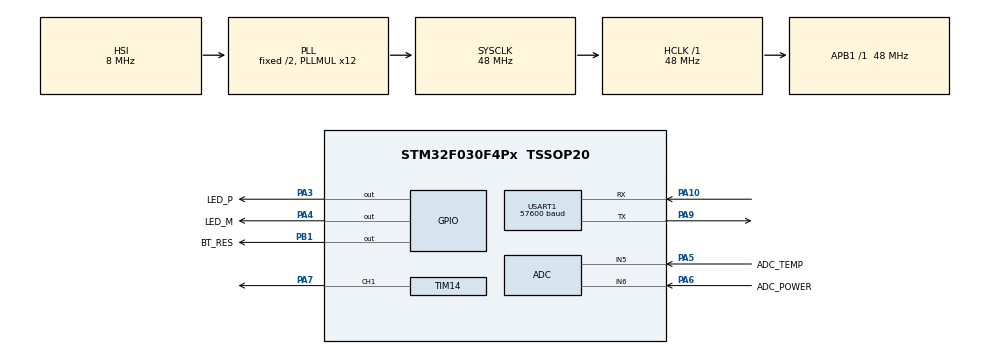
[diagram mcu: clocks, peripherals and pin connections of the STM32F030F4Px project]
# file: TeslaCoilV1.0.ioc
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ADC.ContinuousConvMode=ENABLE
ADC.DMAContinuousRequests=ENABLE
ADC.EOCSelection=ADC_EOC_SINGLE_CONV
ADC.SamplingTime=ADC_SAMPLETIME_239CYCLES_5
Dma.ADC.1.Direction=DMA_PERIPH_TO_MEMORY
Dma.ADC.1.Instance=DMA1_Channel1
Dma.ADC.1.MemDataAlignment=DMA_MDATAALIGN_WORD
Dma.ADC.1.MemInc=DMA_MINC_ENABLE
Dma.ADC.1.Mode=DMA_CIRCULAR
Dma.ADC.1.PeriphDataAlignment=DMA_PDATAALIGN_WORD
Dma.ADC.1.PeriphInc=DMA_PINC_DISABLE
Dma.ADC.1.Priority=DMA_PRIORITY_LOW
Dma.Request0=USART1_TX
Dma.Request1=ADC
Dma.USART1_TX.0.Direction=DMA_MEMORY_TO_PERIPH
Dma.USART1_TX.0.Instance=DMA1_Channel2
Dma.USART1_TX.0.MemDataAlignment=DMA_MDATAALIGN_BYTE
Dma.USART1_TX.0.MemInc=DMA_MINC_ENABLE
Dma.USART1_TX.0.Mode=DMA_NORMAL
Dma.USART1_TX.0.PeriphDataAlignment=DMA_PDATAALIGN_BYTE
Dma.USART1_TX.0.PeriphInc=DMA_PINC_DISABLE
Dma.USART1_TX.0.Priority=DMA_PRIORITY_MEDIUM
Mcu.Family=STM32F0
Mcu.Name=STM32F030F4Px
Mcu.Package=TSSOP20
NVIC.DMA1_Channel1_IRQn=true\:3\:0\:true\:false\:true\:false\:true
NVIC.DMA1_Channel2_3_IRQn=true\:1\:0\:true\:false\:true\:false\:true
NVIC.TIM1_BRK_UP_TRG_COM_IRQn=true\:2\:0\:true\:true\:true\:2\:true\:true
NVIC.USART1_IRQn=true\:1\:0\:true\:true\:true\:1\:true\:true
PA10.GPIO_PuPd=GPIO_NOPULL
PA10.Mode=Asynchronous
PA10.Signal=USART1_RX
PA13.Mode=Serial_Wire
PA13.Signal=SYS_SWDIO
PA14.Mode=Serial_Wire
PA14.Signal=SYS_SWCLK
PA3.GPIO_Label=LED_P
PA3.Signal=GPIO_Output
PA4.GPIO_Label=LED_M
PA4.PinState=GPIO_PIN_SET
PA4.Signal=GPIO_Output
PA5.GPIO_Label=ADC_TEMP
PA5.Mode=IN5
PA5.Signal=ADC_IN5
PA6.GPIO_Label=ADC_POWER
PA6.Mode=IN6
PA6.Signal=ADC_IN6
PA7.Signal=S_TIM14_CH1
PA9.GPIO_PuPd=GPIO_PULLUP
PA9.Mode=Asynchronous
PA9.Signal=USART1_TX
PB1.GPIO_Label=BT_RES
PB1.GPIO_ModeDefaultOutputPP=GPIO_MODE_OUTPUT_OD
PB1.GPIO_PuPd=GPIO_PULLUP
PB1.PinState=GPIO_PIN_SET
PB1.Signal=GPIO_Output
ProjectManager.HeapSize=0x200
ProjectManager.StackSize=0x400
ProjectManager.TargetToolchain=EWARM V8
RCC.AHBFreq_Value=48000000
RCC.APB1Freq_Value=48000000
RCC.APB1TimFreq_Value=48000000
RCC.HCLKFreq_Value=48000000
RCC.PLLMUL=RCC_PLL_MUL12
RCC.SYSCLKFreq_VALUE=48000000
RCC.SYSCLKSource=RCC_SYSCLKSOURCE_PLLCLK
SH.S_TIM14_CH1.0=TIM14_CH1,PWM Generation1 CH1
TIM1.Prescaler=47
TIM14.Channel=TIM_CHANNEL_1
TIM14.OCFastMode_PWM=TIM_OCFAST_ENABLE
TIM14.Period=499
TIM14.Prescaler=47
TIM14.Pulse=1
TIM16.AutoReloadPreload=TIM_AUTORELOAD_PRELOAD_ENABLE
TIM16.Period=999
TIM16.Prescaler=47
USART1.BaudRate=57600
USART1.VirtualMode-Asynchronous=VM_ASYNC
VP_ADC_TempSens_Input.Mode=IN-TempSens
VP_ADC_Vref_Input.Mode=IN-Vrefint
VP_TIM14_VS_ClockSourceINT.Mode=Enable_Timer
VP_TIM16_VS_ClockSourceINT.Mode=Enable_Timer
VP_TIM1_VS_ClockSourceINT.Mode=Internal
board=custom

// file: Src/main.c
/* USER CODE BEGIN Header */
/**
  ******************************************************************************
  * @file           : main.c
  * @brief          : Main program body
  ******************************************************************************
  * @attention
  *
  * <h2><center>&copy; Copyright (c) 2020 STMicroelectronics.
  * All rights reserved.</center></h2>
  *
  * This software component is licensed by ST under BSD 3-Clause license,
  * the "License"; You may not use this file except in compliance with the
  * License. You may obtain a copy of the License at:
  *                        opensource.org/licenses/BSD-3-Clause
  *
  ******************************************************************************
  */
/* USER CODE END Header */

#include "main.h"
#include "adc.h"
#include "dma.h"
#include "tim.h"
#include "usart.h"
#include "gpio.h"

/* USER CODE BEGIN Includes */

#include "System.h"
#include "LED.h"
#include "Connection.h"
#include "ProcessInterrupterData.h"

/* USER CODE END Includes */

void SystemClock_Config(void);
static void MX_NVIC_Init(void);

int main(void)
{

  /* MCU Configuration--------------------------------------------------------*/

  /* Reset of all peripherals, Initializes the Flash interface and the Systick. */
  HAL_Init();

  /* Configure the system clock */
  SystemClock_Config();

  /* Initialize all configured peripherals */
  MX_GPIO_Init();
  MX_DMA_Init();
  MX_TIM14_Init();
  MX_USART1_UART_Init();
  MX_TIM16_Init();
  MX_ADC_Init();
  MX_TIM1_Init();

  /* Initialize interrupts */
  MX_NVIC_Init();

  /* Infinite loop */
  while (1)
  {

    /* USER CODE BEGIN 3 */

    if(htim16.Instance->SR & TIM_SR_UIF) {
      htim16.Instance->SR &= ~TIM_SR_UIF;

      processLed();
      processBluetoothEventTimer();
      processConnectionEventTimer();
      processModulaterInterrupter();
    }

    processSystem();

  }
  /* USER CODE END 3 */
}

void SystemClock_Config(void)
{
  RCC_OscInitTypeDef RCC_OscInitStruct = {0};
  RCC_ClkInitTypeDef RCC_ClkInitStruct = {0};
  RCC_PeriphCLKInitTypeDef PeriphClkInit = {0};

  /** Initializes the CPU, AHB and APB busses clocks
  */
  RCC_OscInitStruct.OscillatorType = RCC_OSCILLATORTYPE_HSI|RCC_OSCILLATORTYPE_HSI14;
  RCC_OscInitStruct.HSIState = RCC_HSI_ON;
  RCC_OscInitStruct.HSI14State = RCC_HSI14_ON;
  RCC_OscInitStruct.HSICalibrationValue = RCC_HSICALIBRATION_DEFAULT;
  RCC_OscInitStruct.HSI14CalibrationValue = 16;
  RCC_OscInitStruct.PLL.PLLState = RCC_PLL_ON;
  RCC_OscInitStruct.PLL.PLLSource = RCC_PLLSOURCE_HSI;
  RCC_OscInitStruct.PLL.PLLMUL = RCC_PLL_MUL12;
  RCC_OscInitStruct.PLL.PREDIV = RCC_PREDIV_DIV1;
  if (HAL_RCC_OscConfig(&RCC_OscInitStruct) != HAL_OK)
  {
    Error_Handler();
  }
  /** Initializes the CPU, AHB and APB busses clocks
  */
  RCC_ClkInitStruct.ClockType = RCC_CLOCKTYPE_HCLK|RCC_CLOCKTYPE_SYSCLK
                              |RCC_CLOCKTYPE_PCLK1;
  RCC_ClkInitStruct.SYSCLKSource = RCC_SYSCLKSOURCE_PLLCLK;
  RCC_ClkInitStruct.AHBCLKDivider = RCC_SYSCLK_DIV1;
  RCC_ClkInitStruct.APB1CLKDivider = RCC_HCLK_DIV1;

  if (HAL_RCC_ClockConfig(&RCC_ClkInitStruct, FLASH_LATENCY_1) != HAL_OK)
  {
    Error_Handler();
  }
  PeriphClkInit.PeriphClockSelection = RCC_PERIPHCLK_USART1;
  PeriphClkInit.Usart1ClockSelection = RCC_USART1CLKSOURCE_PCLK1;
  if (HAL_RCCEx_PeriphCLKConfig(&PeriphClkInit) != HAL_OK)
  {
    Error_Handler();
  }
}

/**
  * @brief NVIC Configuration.
  * @retval None
  */
static void MX_NVIC_Init(void)
{
  /* USART1_IRQn interrupt configuration */
  HAL_NVIC_SetPriority(USART1_IRQn, 1, 0);
  HAL_NVIC_EnableIRQ(USART1_IRQn);
  /* TIM1_BRK_UP_TRG_COM_IRQn interrupt configuration */
  HAL_NVIC_SetPriority(TIM1_BRK_UP_TRG_COM_IRQn, 2, 0);
  HAL_NVIC_EnableIRQ(TIM1_BRK_UP_TRG_COM_IRQn);
}

void Error_Handler(void)
{
  /* USER CODE BEGIN Error_Handler_Debug */
  /* User can add his own implementation to report the HAL error return state */

  setStatusLed(ERROR_HANDLER_LED);

  /* USER CODE END Error_Handler_Debug */
}

#ifdef  USE_FULL_ASSERT
/**
  * @brief  Reports the name of the source file and the source line number
  *         where the assert_param error has occurred.
  * @param  file: pointer to the source file name
  * @param  line: assert_param error line source number
  * @retval None
  */
void assert_failed(char *file, uint32_t line)
{
  /* USER CODE BEGIN 6 */
  /* User can add his own implementation to report the file name and line number,
     tex: printf("Wrong parameters value: file %s on line %d\r\n", file, line) */
  printf("Wrong parameters value: file %s on line %d\r\n", file, line)
  /* USER CODE END 6 */
}
#endif /* USE_FULL_ASSERT */

/************************ (C) COPYRIGHT STMicroelectronics *****END OF FILE****/
